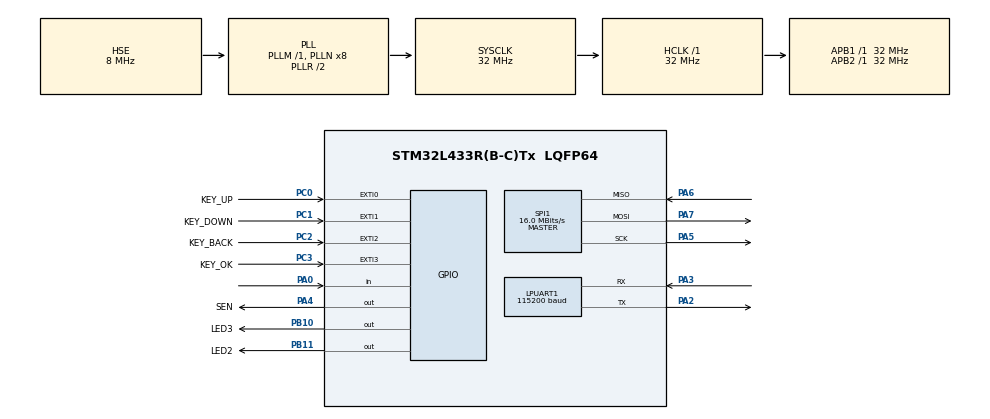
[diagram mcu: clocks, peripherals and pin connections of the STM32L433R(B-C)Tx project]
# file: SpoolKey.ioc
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LPUART1.BaudRate=115200
LPUART1.DMADisableonRxErrorParam=UART_ADVFEATURE_DMA_ENABLEONRXERROR
LPUART1.WordLength=UART_WORDLENGTH_8B
Mcu.Family=STM32L4
Mcu.Name=STM32L433R(B-C)Tx
Mcu.Package=LQFP64
NVIC.EXTI0_IRQn=true\:10\:0\:true\:false\:true\:true\:true\:true
NVIC.EXTI1_IRQn=true\:10\:0\:true\:false\:true\:true\:true\:true
NVIC.EXTI2_IRQn=true\:10\:0\:true\:false\:true\:true\:true\:true
NVIC.EXTI3_IRQn=true\:10\:0\:true\:false\:true\:true\:true\:true
NVIC.LPUART1_IRQn=true\:10\:0\:true\:false\:true\:true\:true\:true
NVIC.PriorityGroup=NVIC_PRIORITYGROUP_4
NVIC.TIM1_UP_TIM16_IRQn=true\:15\:0\:false\:false\:true\:false\:true\:true
NVIC.TIM7_IRQn=true\:10\:0\:true\:false\:true\:true\:true\:true
NVIC.TimeBase=TIM1_UP_TIM16_IRQn
NVIC.TimeBaseIP=TIM16
PA0.Signal=GPIO_Input
PA13\ (JTMS-SWDIO).Mode=Serial_Wire
PA13\ (JTMS-SWDIO).Signal=SYS_JTMS-SWDIO
PA14\ (JTCK-SWCLK).Mode=Serial_Wire
PA14\ (JTCK-SWCLK).Signal=SYS_JTCK-SWCLK
PA2.Mode=Asynchronous
PA2.Signal=LPUART1_TX
PA3.GPIO_PuPd=GPIO_PULLUP
PA3.Mode=Asynchronous
PA3.Signal=LPUART1_RX
PA4.GPIO_Label=SEN
PA4.Signal=GPIO_Output
PA5.Mode=Full_Duplex_Master
PA5.Signal=SPI1_SCK
PA6.Mode=Full_Duplex_Master
PA6.Signal=SPI1_MISO
PA7.Mode=Full_Duplex_Master
PA7.Signal=SPI1_MOSI
PB10.GPIO_Label=LED3
PB10.Signal=GPIO_Output
PB11.GPIO_Label=LED2
PB11.Signal=GPIO_Output
PC0.GPIO_Label=KEY_UP
PC0.GPIO_ModeDefaultEXTI=GPIO_MODE_IT_FALLING
PC0.GPIO_PuPd=GPIO_PULLUP
PC0.Signal=GPXTI0
PC1.GPIO_Label=KEY_DOWN
PC1.GPIO_ModeDefaultEXTI=GPIO_MODE_IT_FALLING
PC1.GPIO_PuPd=GPIO_PULLUP
PC1.Signal=GPXTI1
PC2.GPIO_Label=KEY_BACK
PC2.GPIO_ModeDefaultEXTI=GPIO_MODE_IT_FALLING
PC2.GPIO_PuPd=GPIO_PULLUP
PC2.Signal=GPXTI2
PC3.GPIO_Label=KEY_OK
PC3.GPIO_ModeDefaultEXTI=GPIO_MODE_IT_FALLING
PC3.GPIO_PuPd=GPIO_PULLUP
PC3.Signal=GPXTI3
PH0-OSC_IN\ (PH0).Mode=HSE-External-Oscillator
PH0-OSC_IN\ (PH0).Signal=RCC_OSC_IN
PH1-OSC_OUT\ (PH1).Mode=HSE-External-Oscillator
PH1-OSC_OUT\ (PH1).Signal=RCC_OSC_OUT
ProjectManager.HeapSize=0x1000
ProjectManager.StackSize=0x1000
ProjectManager.TargetToolchain=STM32CubeIDE
RCC.ADCFreq_Value=32000000
RCC.AHBFreq_Value=32000000
RCC.APB1Freq_Value=32000000
RCC.APB1TimFreq_Value=32000000
RCC.APB2Freq_Value=32000000
RCC.APB2TimFreq_Value=32000000
RCC.CortexFreq_Value=32000000
RCC.DATA_CACHE_ENABLE=1
RCC.HCLKFreq_Value=32000000
RCC.HSE_VALUE=8000000
RCC.HSI48_VALUE=48000000
RCC.HSI_VALUE=16000000
RCC.LPUART1CLockSelection=RCC_LPUART1CLKSOURCE_HSI
RCC.LSE_VALUE=32768
RCC.MSI_VALUE=4000000
RCC.PLLSourceVirtual=RCC_PLLSOURCE_HSE
RCC.PREFETCH_ENABLE=0
RCC.SYSCLKFreq_VALUE=32000000
RCC.SYSCLKSource=RCC_SYSCLKSOURCE_PLLCLK
RCC.USBFreq_Value=32000000
RCC.VCOOutputFreq_Value=64000000
SPI1.CalculateBaudRate=16.0 MBits/s
SPI1.Direction=SPI_DIRECTION_2LINES
SPI1.Mode=SPI_MODE_MASTER
SPI1.VirtualType=VM_MASTER
SYS.PowerMode=PWR_LDO_SUPPLY
VP_SYS_VS_DBSignals.Mode=DisableDeadBatterySignals
VP_SYS_VS_LPOM.Mode=PowerOptimisation
VP_SYS_VS_tim16.Mode=TIM16
VP_TIM7_VS_ClockSourceINT.Mode=Enable_Timer
board=custom

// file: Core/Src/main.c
/* USER CODE BEGIN Header */
/**
  ******************************************************************************
  * @file           : main.c
  * @brief          : Main program body
  ******************************************************************************
  * @attention
  *
  * Copyright (c) 2025 STMicroelectronics.
  * All rights reserved.
  *
  * This software is licensed under terms that can be found in the LICENSE file
  * in the root directory of this software component.
  * If no LICENSE file comes with this software, it is provided AS-IS.
  *
  ******************************************************************************
  */
/* USER CODE END Header */
#include "main.h"
#include "usart.h"
#include "spi.h"
#include "tim.h"
#include "gpio.h"

/* USER CODE BEGIN Includes */

#include "FreeRTOS.h"
#include "task.h"

#include "CppWrapper.h"
#include <stdio.h>
/* USER CODE END Includes */

/* USER CODE BEGIN PV */

//  TODO: Add to separate freeRTOS debug funciton file
volatile unsigned long ulStatsTimerTicks;

/* USER CODE END PV */

void SystemClock_Config(void);

int main(void)
{

  /* MCU Configuration--------------------------------------------------------*/

  /* Reset of all peripherals, Initializes the Flash interface and the Systick. */
  HAL_Init();

  /* Configure the system clock */
  SystemClock_Config();

  /* Initialize all configured peripherals */
  MX_GPIO_Init();
  MX_TIM7_Init();
  MX_LPUART1_UART_Init();
  MX_SPI1_Init();
  /* USER CODE BEGIN 2 */

  EventLoopC( );

  /* USER CODE END 2 */

  /* Infinite loop */
  while (1)
  {

  }
}

void SystemClock_Config(void)
{
  RCC_OscInitTypeDef RCC_OscInitStruct = {0};
  RCC_ClkInitTypeDef RCC_ClkInitStruct = {0};

  /** Configure the main internal regulator output voltage
  */
  if (HAL_PWREx_ControlVoltageScaling(PWR_REGULATOR_VOLTAGE_SCALE1) != HAL_OK)
  {
    Error_Handler();
  }

  /** Initializes the RCC Oscillators according to the specified parameters
  * in the RCC_OscInitTypeDef structure.
  */
  RCC_OscInitStruct.OscillatorType = RCC_OSCILLATORTYPE_HSI|RCC_OSCILLATORTYPE_HSE;
  RCC_OscInitStruct.HSEState = RCC_HSE_ON;
  RCC_OscInitStruct.HSIState = RCC_HSI_ON;
  RCC_OscInitStruct.HSICalibrationValue = RCC_HSICALIBRATION_DEFAULT;
  RCC_OscInitStruct.PLL.PLLState = RCC_PLL_ON;
  RCC_OscInitStruct.PLL.PLLSource = RCC_PLLSOURCE_HSE;
  RCC_OscInitStruct.PLL.PLLM = 1;
  RCC_OscInitStruct.PLL.PLLN = 8;
  RCC_OscInitStruct.PLL.PLLP = RCC_PLLP_DIV7;
  RCC_OscInitStruct.PLL.PLLQ = RCC_PLLQ_DIV2;
  RCC_OscInitStruct.PLL.PLLR = RCC_PLLR_DIV2;
  if (HAL_RCC_OscConfig(&RCC_OscInitStruct) != HAL_OK)
  {
    Error_Handler();
  }

  /** Initializes the CPU, AHB and APB buses clocks
  */
  RCC_ClkInitStruct.ClockType = RCC_CLOCKTYPE_HCLK|RCC_CLOCKTYPE_SYSCLK
                              |RCC_CLOCKTYPE_PCLK1|RCC_CLOCKTYPE_PCLK2;
  RCC_ClkInitStruct.SYSCLKSource = RCC_SYSCLKSOURCE_PLLCLK;
  RCC_ClkInitStruct.AHBCLKDivider = RCC_SYSCLK_DIV1;
  RCC_ClkInitStruct.APB1CLKDivider = RCC_HCLK_DIV1;
  RCC_ClkInitStruct.APB2CLKDivider = RCC_HCLK_DIV1;

  if (HAL_RCC_ClockConfig(&RCC_ClkInitStruct, FLASH_LATENCY_1) != HAL_OK)
  {
    Error_Handler();
  }
}

/* USER CODE BEGIN 4 */

//TODO: Move functions to RTOS debug file
void ConfigureFreeRTOSDebugTimer(void)
{
	ulStatsTimerTicks =0;
	MX_TIM7_Init();

    HAL_TIM_Base_Start_IT(&htim7);
}

unsigned long GetFreeRTOSDebugCounter(void)
{
	return ulStatsTimerTicks;
}

void vApplicationStackOverflowHook(TaskHandle_t xTask, char *pcTaskName)
{
	while (1)
	{

	};
}

/* USER CODE END 4 */

void HAL_TIM_PeriodElapsedCallback(TIM_HandleTypeDef *htim)
{
  if (htim->Instance == TIM16)
  {
    HAL_IncTick();
  }
}

void Error_Handler(void)
{
  __disable_irq();
  while (1)
  {
  }
}
